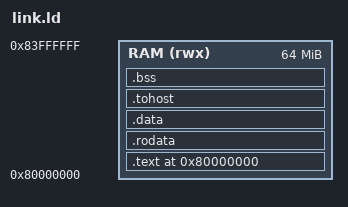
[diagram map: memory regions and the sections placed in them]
OUTPUT_ARCH(riscv)
ENTRY(_start)

MEMORY {
  RAM (rwx) : ORIGIN = 0x80000000, LENGTH = 64M
}

SECTIONS {
  . = ORIGIN(RAM);

  .text : {
    KEEP(*(.text.init))
    *(.text .text.*)
  } > RAM

  .rodata : { *(.rodata .rodata.*) } > RAM
  .data : { *(.data .data.*) } > RAM

  .tohost (NOLOAD) : {
    . = ALIGN(64);
    KEEP(*(.tohost))
  } > RAM

  .bss (NOLOAD) : {
    . = ALIGN(8);
    __bss_start = .;
    *(.bss .bss.*)
    *(COMMON)
    __bss_end = .;
  } > RAM

  __stack_top = ORIGIN(RAM) + LENGTH(RAM);
}
